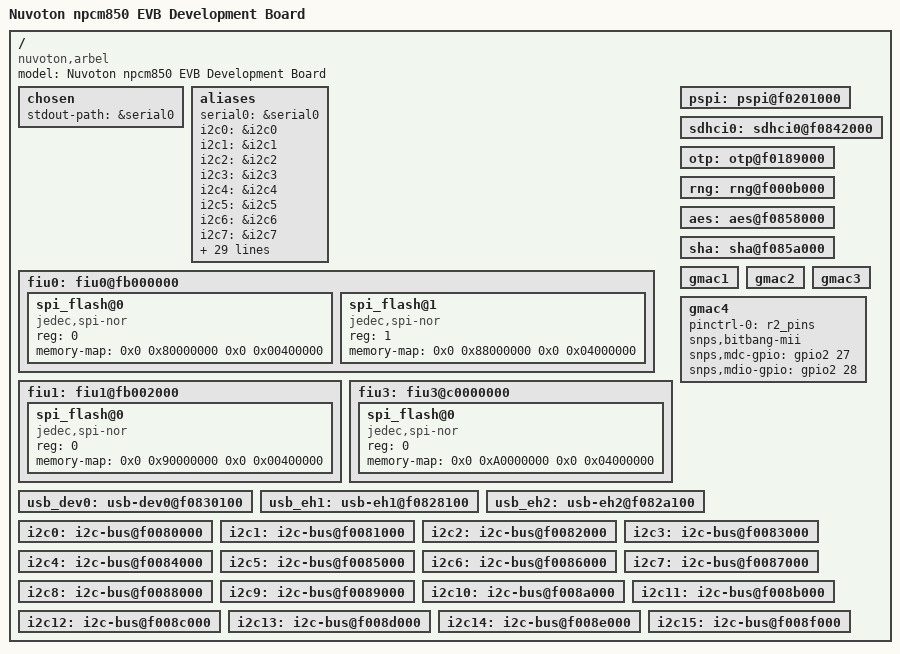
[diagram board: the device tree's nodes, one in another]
/dts-v1/;
#include "nuvoton-common-npcm8xx.dtsi"
#include "nuvoton-npcm850-pincfg.dtsi"


/* Comment below for selecting OHCI_HOST1/2 */
#define USB_EHCI_HOST1
#define USB_EHCI_HOST2


/ {
	model = "Nuvoton npcm850 EVB Development Board";
	compatible = "nuvoton,arbel", "nuvoton,npcm850";

	chosen {
		stdout-path = &serial0;
	};

	aliases {
		serial0 = &serial0;
		i2c0 = &i2c0;
		i2c1 = &i2c1;
		i2c2 = &i2c2;
		i2c3 = &i2c3;
		i2c4 = &i2c4;
		i2c5 = &i2c5;
		i2c6 = &i2c6;
		i2c7 = &i2c7;
		i2c8 = &i2c8;
		i2c9 = &i2c9;
		i2c10 = &i2c10;
		i2c11 = &i2c11;
		i2c12 = &i2c12;
		i2c13 = &i2c13;
		i2c14 = &i2c14;
		i2c15 = &i2c15;
		spi0 = &fiu0;
		spi1 = &fiu1;
		spi3 = &fiu3;
		spi4 = &fiux;
		spi5 = &pspi;
		mmc0 = &sdhci0;
		gpio0 = &gpio0;
		gpio1 = &gpio1;
		gpio2 = &gpio2;
		gpio3 = &gpio3;
		gpio4 = &gpio4;
		gpio5 = &gpio5;
		gpio6 = &gpio6;
		gpio7 = &gpio7;
		usb0 = &usb_dev0;
#ifdef USB_EHCI_HOST1
		usb1 = &usb_eh1;
#else
		usb1 = &usb_oh1;
#endif
#ifdef USB_EHCI_HOST2
		usb2 = &usb_eh2;
#else
		usb2 = &usb_oh2;
#endif
		eth0 = &gmac1;
		eth1 = &gmac2;
		eth2 = &gmac3;
		eth3 = &gmac4;
	};

	fiu0: fiu0@fb000000 {
		status = "okay";
		spi_flash@0 {
			compatible = "jedec,spi-nor";
			reg = <0>; /* CS 0 */
			memory-map = <0x0 0x80000000 0x0 0x00400000>;    /* 4MB */
		};

		spi_flash@1 {
			compatible = "jedec,spi-nor";
			reg = <1>;  /* CS 1 */
			memory-map = <0x0 0x88000000 0x0 0x04000000>;    /* 64MB */
		};
	};

	fiu1: fiu1@fb002000 {
		status = "okay";
		spi_flash@0 {
			compatible = "jedec,spi-nor";
			reg = <0>; /* CS 0 */
			memory-map = <0x0 0x90000000 0x0 0x00400000>;    /* 4MB */
		};
	};

	fiu3: fiu3@c0000000 {
		status = "okay";
		spi_flash@0 {
			compatible = "jedec,spi-nor";
			reg = <0>; /* CS 0 */
			memory-map = <0x0 0xA0000000 0x0 0x04000000>;    /* 64MB */
		};
	};

	pspi: pspi@f0201000 {
		status = "okay";
	};


	sdhci0: sdhci0@f0842000 {
		status = "okay";
	};

	otp: otp@f0189000 {
		status = "okay";
	};

	rng: rng@f000b000 {
		status = "okay";
	};

	aes: aes@f0858000 {
		status = "okay";
	};

	sha: sha@f085a000 {
		status = "okay";
	};

	gmac1: gmac1 {   /* GMAC1- SGMII */
		status = "okay";
	};

	gmac2: gmac2 {   /* GMAC2- RGMII or RMII3 */
		status = "okay";
	};

	gmac3: gmac3 {   /* GMAC3- RMII1 */
		status = "okay";
	};

	gmac4: gmac4 {   /* GMAC4- RMII2 */
		status = "okay";
		pinctrl-names = "default";
		pinctrl-0 = <&r2_pins>;
		snps,bitbang-mii;
		snps,mdc-gpio = <&gpio2 27 GPIO_ACTIVE_HIGH>;    /* gpio91 */
		snps,mdio-gpio = <&gpio2 28 GPIO_ACTIVE_HIGH>;    /* gpio92 */
	};

	usb_dev0: usb-dev0@f0830100 {
		status = "okay";
	};

#ifdef USB_EHCI_HOST1
	usb_eh1: usb-eh1@f0828100 {
		status = "okay";
	};
#else
	usb_oh1: usb-oh1@f0829000 {
		status = "okay";
	};
#endif

#ifdef USB_EHCI_HOST2
	usb_eh2: usb-eh2@f082a100 {
		status = "okay";
	};
#else
	usb_oh2: usb-oh2@f082b000 {
		status = "okay";
	};
#endif

	i2c0: i2c-bus@f0080000 {
		status = "okay";
	};

	i2c1: i2c-bus@f0081000 {
		status = "okay";
	};

	i2c2: i2c-bus@f0082000 {
		status = "okay";
	};

	i2c3: i2c-bus@f0083000 {
		status = "okay";
	};

	i2c4: i2c-bus@f0084000 {
		status = "okay";
	};

	i2c5: i2c-bus@f0085000 {
		status = "okay";
	};

	i2c6: i2c-bus@f0086000 {
		status = "okay";
	};

	i2c7: i2c-bus@f0087000 {
		status = "okay";
	};

	i2c8: i2c-bus@f0088000 {
		status = "okay";
	};

	i2c9: i2c-bus@f0089000 {
		status = "okay";
	};

	i2c10: i2c-bus@f008a000 {
		status = "okay";
	};

	i2c11: i2c-bus@f008b000 {
		status = "okay";
	};

	i2c12: i2c-bus@f008c000 {
		status = "okay";
	};

	i2c13: i2c-bus@f008d000 {
		status = "okay";
	};

	i2c14: i2c-bus@f008e000 {
		status = "okay";
	};

	i2c15: i2c-bus@f008f000 {
		status = "okay";
	};
#if 0
	pinctrl: pinctrl@f0800000 {
		pinctrl-names = "default";
		pinctrl-0 = <
				&clkout_pins
				&gpi36_pins
				&gpi35_pins
				&gpio153_pins
				&gpio71_pins
				&gpio76_pins
				&gpio77_pins
				&gpio202_pins
				&tp_gpio0_pins
				&tp_gpio1_pins
				&jm1_pins
				&j2j3_pins
				&gpio141ol_pins
				&gpio72_pins
				&gpio70o_pins
				&gpio17_pins
				&gpio18_pins		/* Disable PD before pspi */
				&gpio19_pins		/* Disable PD before pspi */
				&gpio68o_pins
				&gpio69o_pins
				&gpio61o_pins
				&gpio98o_pins
				&gpio99o_pins
				&gpio196o_pins
				&gpio16o_pins           /* Disable PU before TP_GPIO2 */
				&tp_gpio2_pins
				&bmcuart0a_pins
				&bmcuart1_pins
				&hsi2a_pins
				&tp_uart_pins
				&bu5_pins
				&bu4_pins
				&bu2_pins
				&gpio73_pins
				&gpio74_pins
				&gpio75_pins
				&gpio218_pins
				&gpio219_pins
				&gpio4_pins
				&gpio5_pins
				&gpio6_pins
				&gpio7_pins
				&gpio47_pins
				&gpio100_pins
				&gpio101_pins
				&gpio120ol_pins
				&gpio190o_pins
				&gpio162o_pins
				&gpio94o_pins
				&gpio93o_pins
				&gpio155_pins
				&gpio231_pins
				&gpio194_pins
				&gpio195_pins
				&gpio168_pins
			    >;
	};
#endif
};
